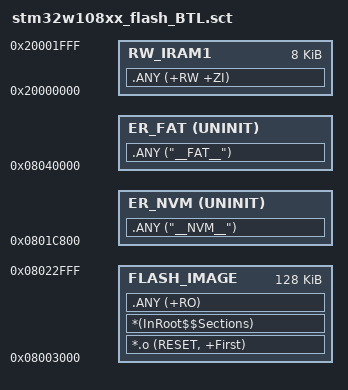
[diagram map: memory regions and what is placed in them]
; *************************************************************
; *** Scatter-Loading Description File generated by uVision ***
; *************************************************************

LR_IROM1 0x08003000 0x00020000  {    ; load region size_region
  FLASH_IMAGE 0x08003000 0x00020000  {  ; load address = execution address
   *.o (RESET, +First)
   *(InRoot$$Sections)
   .ANY (+RO)
  }
  RW_IRAM1 0x20000000 0x00002000  {  ; RW data
   .ANY (+RW +ZI)
  }

    ER_NVM 0x0801C800 UNINIT    {  ; NVM Area
   .ANY ("__NVM__")
  }

    ER_FAT 0x08040000 UNINIT  {   ; FAT Area
   .ANY ("__FAT__")
  }
}

